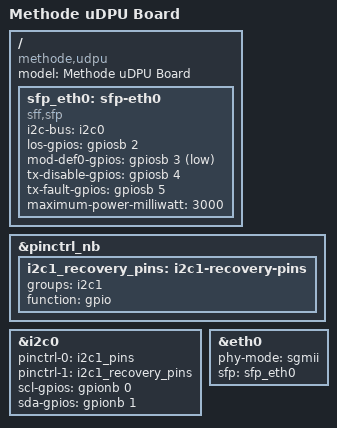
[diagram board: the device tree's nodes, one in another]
// SPDX-License-Identifier: (GPL-2.0+ OR MIT)

/dts-v1/;

#include "armada-3720-uDPU.dtsi"

/ {
	model = "Methode uDPU Board";
	compatible = "methode,udpu", "marvell,armada3720", "marvell,armada3710";

	sfp_eth0: sfp-eth0 {
		compatible = "sff,sfp";
		i2c-bus = <&i2c0>;
		los-gpios = <&gpiosb 2 GPIO_ACTIVE_HIGH>;
		mod-def0-gpios = <&gpiosb 3 GPIO_ACTIVE_LOW>;
		tx-disable-gpios = <&gpiosb 4 GPIO_ACTIVE_HIGH>;
		tx-fault-gpios = <&gpiosb 5 GPIO_ACTIVE_HIGH>;
		maximum-power-milliwatt = <3000>;
	};
};

&pinctrl_nb {
	i2c1_recovery_pins: i2c1-recovery-pins {
		groups = "i2c1";
		function = "gpio";
	};
};

&i2c0 {
	status = "okay";
	pinctrl-names = "default", "recovery";
	pinctrl-0 = <&i2c1_pins>;
	pinctrl-1 = <&i2c1_recovery_pins>;
	/delete-property/mrvl,i2c-fast-mode;
	scl-gpios = <&gpionb 0 (GPIO_ACTIVE_HIGH | GPIO_OPEN_DRAIN)>;
	sda-gpios = <&gpionb 1 (GPIO_ACTIVE_HIGH | GPIO_OPEN_DRAIN)>;
};

&eth0 {
	phy-mode = "sgmii";
	sfp = <&sfp_eth0>;
};
